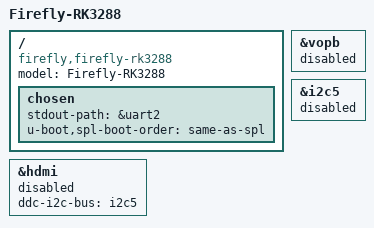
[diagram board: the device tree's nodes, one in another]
// SPDX-License-Identifier: GPL-2.0+ OR X11
/*
 * Copyright (c) 2014, 2015 FUKAUMI Naoki <naobsd@gmail.com>
 */

/dts-v1/;
#include "rk3288-firefly.dtsi"

/ {
	model = "Firefly-RK3288";
	compatible = "firefly,firefly-rk3288", "rockchip,rk3288";

	chosen {
		stdout-path = &uart2;
		u-boot,spl-boot-order = \
			"same-as-spl", &sdmmc, &emmc;
	};
};

&vopb {
	status = "disabled";
};

&hdmi {
	ddc-i2c-bus = <&i2c5>;
	status = "disabled";
};

&i2c5 {
	status = "disabled";
};
